# MDR1986VK214 register map
Vendor: Milandr; Series: ARMCM0; File version: 2.0
CPU: CM0 r0p0, little endian, no MPU, no FPU, 2 interrupt priority bits
Registers are 32-bit, read-write, reset 0x0 unless marked. A register's access mark holds for its fields unless they carry their own. Offsets are from the block's base; [hi:lo] are bit positions; 'fields as' and 'values as' point back to an identical list.

## MDR_ADCUI — Energy Counter Block
Base 0x40068000
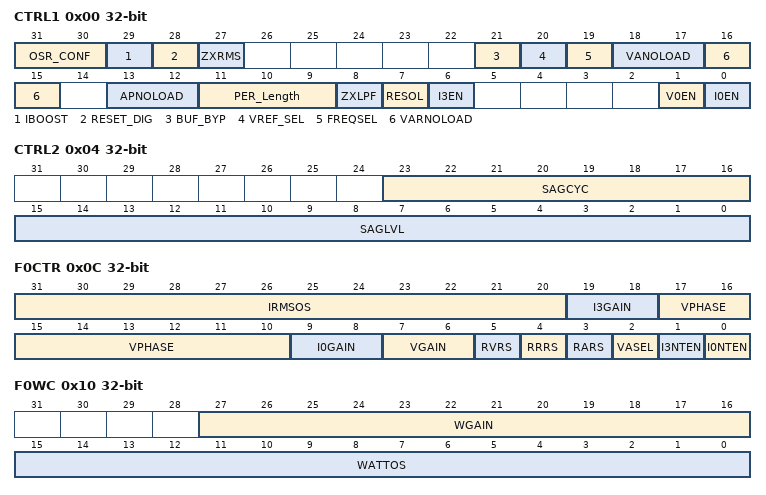
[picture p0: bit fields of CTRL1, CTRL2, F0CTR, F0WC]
0x00 CTRL1 — ADCUI Control1 Register
  [31:30] OSR_CONF — ADC Output Sampling Rate
    0=4kHz (Sampling at 4kHz); 1=8kHz (Sampling at 8kHz); 2=16kHz (Sampling at 16kHz)
  [29] IBOOST — Boost I mode
    0=Normal (Working mode); 1=Boost I enabled
  [28] RESET_DIG — Digital Logic Reset
    0=Inactive (Working mode); 1=Reset (Logic in reset)
  [27] ZXRMS — RMS Update mode
    0=Continuous RMS update; 1=OnZeroV0 (Update on V0 cross zero level)
  [21] BUF_BYP — Bypass Vref buffer
    0=Buffered (Vref through buffer); 1=NotBuffered (Vref bypass buffer)
  [20] VREF_SEL — ADC Vref select
    0=Internal Vref source; 1=External Vref source
  [19] FREQSEL — Enable V0 period detection to FxMD0.PER_FREQ
    0=Off (Hold Last value); 1=On (Enabled)
  [18:17] VANOLOAD — Full Energy min level to accumulate
    0=All (Accunulate All Energy); 1=lv_012 (Pass E less than 0.012%); 2=lv_0061 (Pass E less than 0.0061%); 3=lv_00305 (Pass E less than 0.00305%)
  [16:15] VARNOLOAD — Reactive Energy min level to accumulate
    values as VANOLOAD
  [13:12] APNOLOAD — Active Energy min level to accumulate
    values as VANOLOAD
  [11:9] PER_Length — Period to calc aver period and dPhase
    0=Period_1 (1 period); 1=Period_2 (2 periods); 2=Period_3 (4 periods); 3=Period_4 (8 periods); 4=Period_5 (16 periods); 5=Period_6 (32 periods); 6=Period_7 (64 periods); 7=Period_8 (128 periods)
  [8] ZXLPF — V0 cross zero LPF enable
    0=On (Enabled); 1=Off (Disable)
  [7] RESOL — Data resolution
    0=bit_16 (16 bit data); 1=bit_24 (24 bit data)
  [6] I3EN — Channel enable
    0=Off (Disabled); 1=On (Enabled)
  [1] V0EN — Channel enable
    0=Off (Disabled); 1=On (Enabled)
  [0] I0EN — Channel enable
    0=Off (Disabled); 1=On (Enabled)
0x04 CTRL2 — ADCUI Control2 Register
  [23:16] SAGCYC — Count of V0 half periods to calc V0 level
  [15:0] SAGLVL — V0 min OK level
0x08 CTRL3 — ADCUI Control3 Register
  [11:0] ZTXOUT — V0 cross zero timeout
0x0C F0CTR — FxCTR register
  [31:20] IRMSOS — RMS calibration of channel I
  [19:18] I3GAIN — PGA value
    0=Signal amplification 0dB; 1=x2 (Signal amplification 6dB); 2=x4 (Signal amplification 12dB); 3=x8 (Signal amplification 18dB)
  [17:10] VPHASE — Phase V0 adjustment by step of +-124us
  [9:8] I0GAIN — PGA value
    values as I3GAIN
  [7:6] VGAIN — PGA value
    values as I3GAIN
  [5] RVRS wo — Full Energy Accumulator Reset
    0=Inactive state; 1=Clear (Accumulator sets to zero)
  [4] RRRS wo — Reactive Energy Accumulator Reset
    0=Inactive state; 1=Clear (Accumulator sets to zero)
  [3] RARS wo — Active Energy Accumulator Reset
    0=Inactive state; 1=Clear (Accumulator sets to zero)
  [2] VASEL — Select source for FullEnergy
    0=FullEnergy (I0DAT and VDAT can store FullEnergy); 1=I_RMS (I0DAT and VDAT can store I_RMS)
  [1] I3NTEN — Integrator enable
    0=Off (Disabled); 1=On (Enabled)
  [0] I0NTEN — Integrator enable
    0=Off (Disabled); 1=On (Enabled)
0x10 F0WC — Active energy calibration
  [27:16] WGAIN — Calibr gain of active energy
  [15:0] WATTOS — Calibr bias of active energy
0x14 F0WATTP ro — Positive Active Energy accumulator
  [31:0] WATTHRP — High 32 bits of Accumulator
0x18 F0WATTN ro — Negative Active Energy accumulator
  [31:0] WATTHRN — High 32 bits of 57bits Accumulator
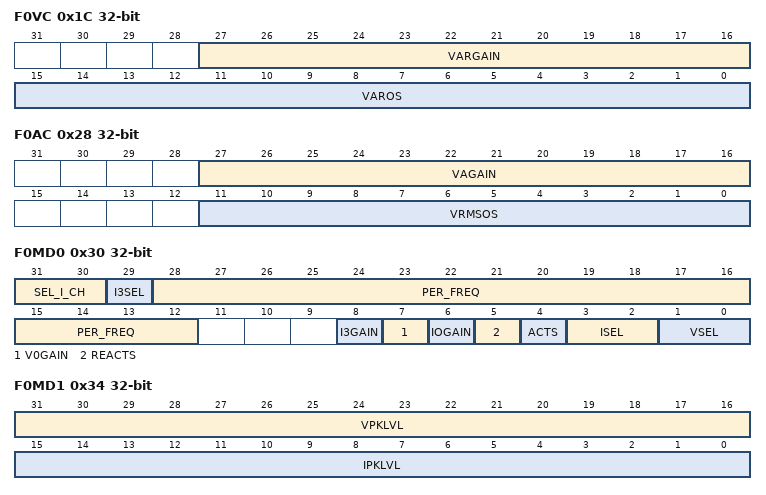
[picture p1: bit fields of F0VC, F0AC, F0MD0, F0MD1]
0x1C F0VC — Reactive energy calibration
  [27:16] VARGAIN — Calibr gain of reactive energy
  [15:0] VAROS — Calibr bias of reactive energy
0x20 F0VARP ro — Positive Reactive Energy accumulator
  [31:0] VARHRP — High 32 bits of of 57bits Accumulator
0x24 F0VARN ro — Negative Reactive Energy accumulator
  [31:0] VARHRN — High 32 bits of of 57bits Accumulator
0x28 F0AC — V0 RMS calibration
  [27:16] VAGAIN — Calibr gain of Full energy
  [11:0] VRMSOS — Calibr bias of V0 RMS
0x2C F0VR ro — Full Energy accumulator
  [31:0] VAHR — High 32 bits of of 57bits Accumulator
0x30 F0MD0 — FxMD0 register
  [31:30] SEL_I_CH — Select I for calc power
    0=Auto_max (Select max of I0 and I3); 1=I0 (Calc Power by I0); 2=I3 (Calc Power by I3)
  [29] I3SEL — Select source for FxI3DAT
    0=I3_LPF (Signal after LPF); 1=ADC_I3 (ADC_I3 output)
  [28:12] PER_FREQ ro — Measured period of V
  [8] I3GAIN — ADC Decimation gain
    0=No gain; 1=x2 (Gain by +6dB)
  [7] V0GAIN — ADC Decimation gain
    0=No gain; 1=x2 (Gain by +6dB)
  [6] IOGAIN — ADC Decimation gain
    0=No gain; 1=x2 (Gain by +6dB)
  [5] REACTS ro — Reactive Energy sign in last period
    0=Pos (Positive sign); 1=Neg (Negative sign)
  [4] ACTS ro — Active Energy sign in last period
    0=Pos (Positive sign); 1=Neg (Negative sign)
  [3:2] ISEL — Select source for FxI0DAT
    0=ADC_I0 (ADC_I0 output); 1=ActivePower; 2=ReactivePower; 3=FullPower
  [1:0] VSEL — Select source for FxVDAT
    0=ADC_V (ADC_V output); 1=ActivePower; 2=ReactivePower; 3=FullPower
0x34 F0MD1 (reset mask 0xFFFFFF) — FxMD1 register
  [31:16] VPKLVL — Vmax level
  [15:0] IPKLVL — Imax level
0x38 F0VPEAK — VPEAK Result register
  [23:0] IPEAK — Vmax measured, write any to clear
0x3C F0IPEAK — IPEAK Result register
  [23:0] IPEAK — Imax measured, write any to clear
0x40 F0VDAT ro — VDAT Result register
  [23:0] VDAT — FIFO of V or Power
0x44 F0I0DAT ro — I0DAT Result register
  [23:0] I0DAT — FIFO of I0 or Power
0x48 F0I3DAT ro — I3DAT Result register
  [23:0] I3DAT — FIFO of I3 or Power
0x4C F0VRMS ro — VRMS Result register
  [23:0] VRMS — RMS of V
0x50 F0VRMS2 ro — VRMS^2 Result register
  [23:0] VRMS2 — RMS of V^2
0x54 F0IRMS ro — IRMS Result register
  [23:0] IRMS — RMS of I
0x58 F0IRMS2 ro — IRMS^2 Result register
  [23:0] IRMS2 — RMS of I^2
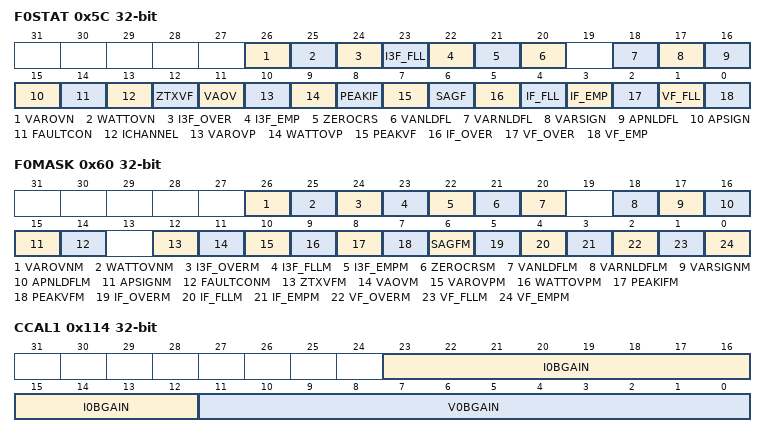
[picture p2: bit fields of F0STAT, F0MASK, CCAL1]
0x5C F0STAT — Status Register
  [26] VAROVN — FxVARN value overflow
    0=Off (Disabled); 1=On (Enabled)
  [25] WATTOVN — FxWATTN value overflow
    0=Off (Disabled); 1=On (Enabled)
  [24] I3F_OVER — FIFO_I3DAT is Overflow
    0=Off (Disabled); 1=On (Enabled)
  [23] I3F_FLL ro — FIFO_I3DAT is Full
    0=Off (Disabled); 1=On (Enabled)
  [22] I3F_EMP ro — FIFO_I3DAT is Empty
    0=Off (Disabled); 1=On (Enabled)
  [21] ZEROCRS — V crossed zero
    0=Off (Disabled); 1=On (Enabled)
  [20] VANLDFL ro — FullPower less CNTL1.VANOLOAD
    0=Off (Disabled); 1=On (Enabled)
  [18] VARNLDFL ro — ReactivePower less CNTL1.VARNOLOAD
    0=Off (Disabled); 1=On (Enabled)
  [17] VARSIGN — ReactivePower sign changed
    0=Off (Disabled); 1=On (Enabled)
  [16] APNLDFL ro — ActivePower less CNTL1.APNOLOAD
    0=Off (Disabled); 1=On (Enabled)
  [15] APSIGN — ActivePower sign changed
    0=Off (Disabled); 1=On (Enabled)
  [14] FAULTCON — Active I switched
    0=Off (Disabled); 1=On (Enabled)
  [13] ICHANNEL ro — Timeout of V cross zero
    0=I0 (I0 is active); 1=I3 (I3 is active)
  [12] ZTXVF — Timeout of V cross zero
    0=Off (Disabled); 1=On (Enabled)
  [11] VAOV — FxVR value overflow
    0=Off (Disabled); 1=On (Enabled)
  [10] VAROVP — FxVARP value overflow
    0=Off (Disabled); 1=On (Enabled)
  [9] WATTOVP — FxWATTP value overflow
    0=Off (Disabled); 1=On (Enabled)
  [8] PEAKIF — I exceeds F0MD1.VPKLVL
    0=Off (Disabled); 1=On (Enabled)
  [7] PEAKVF — V exceeds F0MD1.VPKLVL
    0=Off (Disabled); 1=On (Enabled)
  [6] SAGF — V is less than CTRL2.SAGLVL
    0=Off (Disabled); 1=On (Enabled)
  [5] IF_OVER — FIFO_IDAT is Overflow
    0=Off (Disabled); 1=On (Enabled)
  [4] IF_FLL ro — FIFO_IDAT is Full
    0=Off (Disabled); 1=On (Enabled)
  [3] IF_EMP ro — FIFO_IDAT is Empty
    0=Off (Disabled); 1=On (Enabled)
  [2] VF_OVER — FIFO_VDAT is Overflow
    0=Off (Disabled); 1=On (Enabled)
  [1] VF_FLL ro — FIFO_VDAT is Full
    0=Off (Disabled); 1=On (Enabled)
  [0] VF_EMP ro — FIFO_VDAT is Empty
    0=Off (Disabled); 1=On (Enabled)
0x60 F0MASK — IRQ Mask Register
  [all] fields
    0=Off (Disabled); 1=On (Enabled)
  [26] VAROVNM — FxVARN value overflow
  [25] WATTOVNM — FxWATTN value overflow
  [24] I3F_OVERM — FIFO_I3DAT is Overflow
  [23] I3F_FLLM — FIFO_I3DAT is Full
  [22] I3F_EMPM — FIFO_I3DAT is Empty
  [21] ZEROCRSM — V crossed zero
  [20] VANLDFLM — FullPower less CNTL1.VANOLOAD
  [18] VARNLDFLM — ReactivePower less CNTL1.VARNOLOAD
  [17] VARSIGNM — ReactivePower sign changed
  [16] APNLDFLM — ActivePower less CNTL1.APNOLOAD
  [15] APSIGNM — ActivePower sign changed
  [14] FAULTCONM — Active I switched
  [12] ZTXVFM — Timeout of V cross zero
  [11] VAOVM — FxVR value overflow
  [10] VAROVPM — FxVARP value overflow
  [9] WATTOVPM — FxWATTP value overflow
  [8] PEAKIFM — I exceeds F0MD1.VPKLVL
  [7] PEAKVFM — V exceeds F0MD1.VPKLVL
  [6] SAGFM — V is less than CTRL2.SAGLVL
  [5] IF_OVERM — FIFO_IDAT is Overflow
  [4] IF_FLLM — FIFO_IDAT is Full
  [3] IF_EMPM — FIFO_IDAT is Empty
  [2] VF_OVERM — FIFO_VDAT is Overflow
  [1] VF_FLLM — FIFO_VDAT is Full
  [0] VF_EMPM — FIFO_VDAT is Empty
0x114 CCAL1 — Calibration Register 1
  [23:12] I0BGAIN — I0 calibration gain
  [11:0] V0BGAIN — V0 calibration gain
0x120 CCAL4 — Calibration Register 4
  [11:0] I3BGAIN — I3 calibration gain
